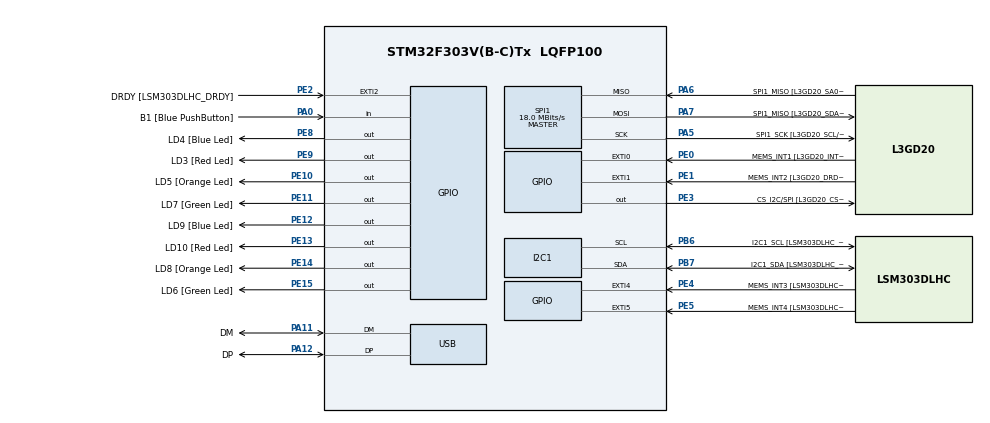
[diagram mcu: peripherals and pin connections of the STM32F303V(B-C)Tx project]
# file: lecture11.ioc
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FREERTOS.Tasks01=defaultTask,0,128,StartDefaultTask,Default,NULL,Dynamic,NULL,NULL;myTask02,-3,128,StartTask02,Default,NULL,Dynamic,NULL,NULL;myTask03,-3,128,StartTask03,Default,NULL,Dynamic,NULL,NULL
I2C1.Timing-I2C=0x2000090E
Mcu.Family=STM32F3
Mcu.Name=STM32F303V(B-C)Tx
Mcu.Package=LQFP100
NVIC.PriorityGroup=NVIC_PRIORITYGROUP_4
NVIC.TIM1_UP_TIM16_IRQn=true\:0\:0\:false\:false\:true\:false\:false
NVIC.TimeBase=TIM1_UP_TIM16_IRQn
NVIC.TimeBaseIP=TIM1
PA0.GPIO_Label=B1 [Blue PushButton]
PA0.Signal=GPIO_Input
PA11.GPIO_Label=DM
PA11.Mode=Device
PA11.Signal=USB_DM
PA12.GPIO_Label=DP
PA12.Mode=Device
PA12.Signal=USB_DP
PA13.GPIO_Label=SWDIO
PA13.Mode=Serial_Wire
PA13.Signal=SYS_JTMS-SWDIO
PA14.GPIO_Label=SWCLK
PA14.Mode=Serial_Wire
PA14.Signal=SYS_JTCK-SWCLK
PA5.GPIO_Label=SPI1_SCK [L3GD20_SCL/SPC]
PA5.Mode=Full_Duplex_Master
PA5.Signal=SPI1_SCK
PA6.GPIO_Label=SPI1_MISO [L3GD20_SA0/SDO]
PA6.Mode=Full_Duplex_Master
PA6.Signal=SPI1_MISO
PA7.GPIO_Label=SPI1_MISO [L3GD20_SDA/SDI/SDO]
PA7.Mode=Full_Duplex_Master
PA7.Signal=SPI1_MOSI
PB3.GPIO_Label=SWO
PB3.Signal=SYS_JTDO-TRACESWO
PB6.GPIO_Label=I2C1_SCL [LSM303DLHC_SCL]
PB6.Mode=I2C
PB6.Signal=I2C1_SCL
PB7.GPIO_Label=I2C1_SDA [LSM303DLHC_SDA]
PB7.Mode=I2C
PB7.Signal=I2C1_SDA
PC14-OSC32_IN.GPIO_Label=OSC32_IN
PC14-OSC32_IN.Signal=RCC_OSC32_IN
PC15-OSC32_OUT.GPIO_Label=OSC32_OUT
PC15-OSC32_OUT.Signal=RCC_OSC32_OUT
PE0.GPIO_Label=MEMS_INT1 [L3GD20_INT1]
PE0.GPIO_ModeDefaultEXTI=GPIO_MODE_EVT_RISING
PE0.Signal=GPXTI0
PE1.GPIO_Label=MEMS_INT2 [L3GD20_DRDY/INT2]
PE1.GPIO_ModeDefaultEXTI=GPIO_MODE_EVT_RISING
PE1.Signal=GPXTI1
PE10.GPIO_Label=LD5 [Orange Led]
PE10.Signal=GPIO_Output
PE11.GPIO_Label=LD7 [Green Led]
PE11.Signal=GPIO_Output
PE12.GPIO_Label=LD9 [Blue Led]
PE12.Signal=GPIO_Output
PE13.GPIO_Label=LD10 [Red Led]
PE13.Signal=GPIO_Output
PE14.GPIO_Label=LD8 [Orange Led]
PE14.Signal=GPIO_Output
PE15.GPIO_Label=LD6 [Green Led]
PE15.Signal=GPIO_Output
PE2.GPIO_Label=DRDY [LSM303DLHC_DRDY]
PE2.GPIO_ModeDefaultEXTI=GPIO_MODE_EVT_RISING
PE2.Signal=GPXTI2
PE3.GPIO_Label=CS_I2C/SPI [L3GD20_CS_I2C/SPI]
PE3.Signal=GPIO_Output
PE4.GPIO_Label=MEMS_INT3 [LSM303DLHC_INT1]
PE4.GPIO_ModeDefaultEXTI=GPIO_MODE_EVT_RISING
PE4.Signal=GPXTI4
PE5.GPIO_Label=MEMS_INT4 [LSM303DLHC_INT2]
PE5.GPIO_ModeDefaultEXTI=GPIO_MODE_EVT_RISING
PE5.Signal=GPXTI5
PE8.GPIO_Label=LD4 [Blue Led]
PE8.Signal=GPIO_Output
PE9.GPIO_Label=LD3 [Red Led]
PE9.Signal=GPIO_Output
PF0-OSC_IN.GPIO_Label=OSC_IN
PF0-OSC_IN.Mode=HSE-External-Clock-Source
PF0-OSC_IN.Signal=RCC_OSC_IN
PF1-OSC_OUT.GPIO_Label=OSC_OUT
PF1-OSC_OUT.Signal=RCC_OSC_OUT
ProjectManager.HeapSize=0x2000
ProjectManager.StackSize=0x4000
ProjectManager.TargetToolchain=MDK-ARM V5
RCC.AHBFreq_Value=72000000
RCC.APB1CLKDivider=RCC_HCLK_DIV2
RCC.APB1Freq_Value=36000000
RCC.APB1TimFreq_Value=72000000
RCC.APB2Freq_Value=72000000
RCC.APB2TimFreq_Value=72000000
RCC.CortexFreq_Value=72000000
RCC.HCLKFreq_Value=72000000
RCC.HSE_VALUE=8000000
RCC.HSI_VALUE=8000000
RCC.LSE_VALUE=32768
RCC.PLLMUL=RCC_PLL_MUL9
RCC.PRESCALERUSB=RCC_USBCLKSOURCE_PLL_DIV1_5
RCC.SYSCLKFreq_VALUE=72000000
RCC.SYSCLKSourceVirtual=RCC_SYSCLKSOURCE_PLLCLK
RCC.USBFreq_Value=48000000
SPI1.BaudRatePrescaler=SPI_BAUDRATEPRESCALER_4
SPI1.BaudRatePrescaler-Full_Duplex_Master=SPI_BAUDRATEPRESCALER_2
SPI1.CalculateBaudRate=18.0 MBits/s
SPI1.CalculateBaudRate-Full_Duplex_Master=24.0 MBits/s
SPI1.Direction=SPI_DIRECTION_2LINES
SPI1.Mode=SPI_MODE_MASTER
SPI1.Mode-Full_Duplex_Master=SPI_MODE_MASTER
SPI1.VirtualType=VM_MASTER
VP_FREERTOS_VS_ENABLE.Mode=Enabled
VP_SYS_VS_tim1.Mode=TIM1
board=STM32F3DISCOVERY

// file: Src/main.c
/* USER CODE BEGIN Header */
/**
  ******************************************************************************
  * @file           : main.c
  * @brief          : Create program "The Dining Philosophers"
  ******************************************************************************
  * @attention
  *
  * <h2><center>&copy; Copyright (c) 2020 STMicroelectronics.
  * All rights reserved.</center></h2>
  *
  * This software component is licensed by ST under Ultimate Liberty license
  * SLA0044, the "License"; You may not use this file except in compliance with
  * the License. You may obtain a copy of the License at:
  *                             www.st.com/SLA0044
  *
  ******************************************************************************
  */
/* USER CODE END Header */

#include "main.h"
#include "stm32f3xx_hal.h"
#include "cmsis_os.h"
#include "Init.h"
#include "FreeRTOS.h"
#include "task.h"
#include "queue.h"

/* USER CODE BEGIN Includes */
#define  ARISTOTLE 0
#define  PLATON 1
#define  NIETZSCHE 2
#define  KANT 3
#define  SOCRAT 4
/* USER CODE END Includes */

TaskHandle_t myTaskHandle[5];
/*for each of philosofer*/
SemaphoreHandle_t xSemaphorePhilosofer[5] = {NULL};
/* fork taking */
SemaphoreHandle_t xSemaphoreTakingFork = NULL;

volatile uint32_t TIM1_Count = 0;
volatile uint32_t TIM1_Count_Sec = 0;
volatile uint8_t philosopherStatus[5] = {0};

void Philosopher_1(void* pvParameters);
void Philosopher_2(void* pvParameters);
void Philosopher_3(void* pvParameters);
void Philosopher_4(void* pvParameters);
void Philosopher_5(void* pvParameters);

void t_Fork (uint8_t);
void t_Eat(uint8_t);
void p_Fork (uint8_t);
/* ---------------------------------------------------------------------------*/
int main(void)
{

/* Reset of all peripherals, Initializes the Flash interface and the Systick. */
  HAL_Init();

/* Configure the system clock */
  SystemClock_Config();

  /* Initialize all configured peripherals */
  MX_GPIO_Init();
  MX_I2C1_Init();
  MX_SPI1_Init();
  MX_USB_PCD_Init();
	/* creating semaphors for each forks */
	for(int i = 0; i < 5; i++)
	{
		xSemaphorePhilosofer[i] = xSemaphoreCreateBinary();
		if( xSemaphorePhilosofer[i]  == NULL )
		{    /* There was insufficient FreeRTOS heap available for the semaphore to be created successfully. */
				 for (;;);
		}
		else
		{
				if( xSemaphoreGive( xSemaphorePhilosofer[i]  ) != pdTRUE )
				{
					for (;;);
				}
		}
	}
	/* semaphor for taking fork */
	xSemaphoreTakingFork = xSemaphoreCreateBinary();
	if( xSemaphoreTakingFork  == NULL )
		{    /* There was insufficient FreeRTOS heap available for the semaphore to be created successfully. */
				 for (;;);
		}
		else
		{
				if( xSemaphoreGive(xSemaphoreTakingFork) != pdTRUE )
				{
					for (;;);
				}
		}

		xTaskCreate(Philosopher_1,       /* Function that implements the task. */
								"philosopher1",          /* Text name for the task. */
								64,      /* Stack size in words, not bytes. */
								NULL,    /* Parameter passed into the task. */
								0,/* Priority at which the task is created. */
								&myTaskHandle[0] );

		xTaskCreate(Philosopher_2,       /* Function that implements the task. */
								"philosopher2",          /* Text name for the task. */
								64,      /* Stack size in words, not bytes. */
								NULL,    /* Parameter passed into the task. */
								0,/* Priority at which the task is created. */
								&myTaskHandle[1] );

		xTaskCreate(Philosopher_3,       /* Function that implements the task. */
								"philosopher3",          /* Text name for the task. */
								64,      /* Stack size in words, not bytes. */
								NULL,    /* Parameter passed into the task. */
								0,/* Priority at which the task is created. */
								&myTaskHandle[2] );
		xTaskCreate(Philosopher_4,       /* Function that implements the task. */
								"philosopher4",          /* Text name for the task. */
								64,      /* Stack size in words, not bytes. */
								NULL,    /* Parameter passed into the task. */
								0,/* Priority at which the task is created. */
								&myTaskHandle[3] );
		xTaskCreate(Philosopher_5,       /* Function that implements the task. */
								"philosopher5",          /* Text name for the task. */
								64,      /* Stack size in words, not bytes. */
								NULL,    /* Parameter passed into the task. */
								0,/* Priority at which the task is created. */
								&myTaskHandle[4] );
	/* Start scheduler */
  osKernelStart();

  while (1)
  {
  }
}
/**
  * @brief  executed when one of the philosophers try to take a fork.
  * @param  Number of philosopher who want to take a fork.
  */
void t_Fork (uint8_t philosopher)
{
	if (xSemaphoreTakingFork != NULL)
  {
    if(osSemaphoreWait(xSemaphoreTakingFork , 100) == osOK)
    {
			philosopherStatus[philosopher] = 1;
			/* taking forks */
			t_Eat(philosopher);
			/* taking semaphor for philosofer how waithing for forks */
			osSemaphoreRelease(xSemaphoreTakingFork);
		}
		else
		{
			/* taking semaphor for philosopher how whants to eat */
			xSemaphoreTake( xSemaphorePhilosofer[philosopher],  portMAX_DELAY );
		}
	}
}
/**
  * @brief  executed when one of the philosophers test forks.
  * @param  Number of philosopher who want release the forks.
  */
void t_Eat(uint8_t philosopher)
{
		if (philosopherStatus[philosopher] == 1
				  && philosopherStatus[(philosopher + 5 - 1) % 5] != 2
					&& philosopherStatus[(philosopher + 1) % 5] != 2)
			{
				philosopherStatus[philosopher] = 2;
				xSemaphoreGive( xSemaphorePhilosofer[philosopher] );
			}
}
/**
  * @brief  executed when one of the philosophers releasin the forks.
  * @param  Number of philosopher who want release the forks.
  */
void p_Fork (uint8_t philosopher)
{
	if(osSemaphoreWait(xSemaphoreTakingFork , 100) == osOK)
	{
		philosopherStatus[philosopher] = 0;
		t_Eat((philosopher + 5 - 1) % 5);
		t_Eat((philosopher + 1) % 5);
		osSemaphoreRelease(xSemaphoreTakingFork);
	}
}

void Philosopher_1( void* pvParameters)
{
	for(;;)
  {
		/*  thinking */
		osDelay(100);
		/*  take forks */
		t_Fork (ARISTOTLE);

		if(xSemaphoreTake( xSemaphorePhilosofer[ARISTOTLE],  portMAX_DELAY ) == pdTRUE && philosopherStatus[ARISTOTLE] == 2)
		{
				/* eating */
				HAL_GPIO_WritePin(LEDPORT, LED02, GPIO_PIN_RESET);
				HAL_GPIO_WritePin(LEDPORT, LED01, GPIO_PIN_SET);
				osDelay(100);
				HAL_GPIO_WritePin(LEDPORT, LED01, GPIO_PIN_RESET);
				HAL_GPIO_WritePin(LEDPORT, LED02, GPIO_PIN_SET);
				osDelay(100);
				/* eating */
				xSemaphoreGive( xSemaphorePhilosofer[ARISTOTLE]);
				p_Fork(ARISTOTLE);
		}
		else
		{
			osDelay(10);
		}
	}
}

void Philosopher_2( void* pvParameters)
{
	for(;;)
  {
		/*  thinking */
		osDelay(100);
		/*  take forks */
		t_Fork (PLATON);

		if(xSemaphoreTake( xSemaphorePhilosofer[PLATON],  portMAX_DELAY ) == pdTRUE && philosopherStatus[PLATON] == 2)
		{
				/* eating */
				HAL_GPIO_WritePin(LEDPORT, LED04, GPIO_PIN_RESET);
				HAL_GPIO_WritePin(LEDPORT, LED03, GPIO_PIN_SET);
				osDelay(100);
				HAL_GPIO_WritePin(LEDPORT, LED03, GPIO_PIN_RESET);
				HAL_GPIO_WritePin(LEDPORT, LED04, GPIO_PIN_SET);
				osDelay(100);
				/* eating */
				xSemaphoreGive(xSemaphorePhilosofer[PLATON]);
				p_Fork(PLATON);
			}
		else
		{
			osDelay(10);
		}

	}
}

void Philosopher_3( void* pvParameters)
{
	for(;;)
  {
		/*  thinking */
		osDelay(70);
		/*  take forks */
		t_Fork (NIETZSCHE);

		if(xSemaphoreTake( xSemaphorePhilosofer[NIETZSCHE],  portMAX_DELAY ) == pdTRUE && philosopherStatus[NIETZSCHE] == 2)
		{
				/* eating */
				HAL_GPIO_WritePin(LEDPORT, LED06, GPIO_PIN_RESET);
				HAL_GPIO_WritePin(LEDPORT, LED05, GPIO_PIN_SET);
				osDelay(100);
				HAL_GPIO_WritePin(LEDPORT, LED05, GPIO_PIN_RESET);
				HAL_GPIO_WritePin(LEDPORT, LED06, GPIO_PIN_SET);
				osDelay(100);
				/* eating */
				xSemaphoreGive(xSemaphorePhilosofer[NIETZSCHE]);
				p_Fork(NIETZSCHE);
			}
		else
		{
			osDelay(10);
		}

	}
}

void Philosopher_4( void* pvParameters)
{
	for(;;)
  {
		/*  thinking */
		osDelay(100);
		/*  take forks */
		t_Fork (KANT);

		if(xSemaphoreTake( xSemaphorePhilosofer[KANT],  portMAX_DELAY ) == pdTRUE && philosopherStatus[KANT] == 2)
		{
				/* eating */
				HAL_GPIO_WritePin(LEDPORT, LED08, GPIO_PIN_RESET);
				HAL_GPIO_WritePin(LEDPORT, LED07, GPIO_PIN_SET);
				osDelay(100);
				HAL_GPIO_WritePin(LEDPORT, LED07, GPIO_PIN_RESET);
				HAL_GPIO_WritePin(LEDPORT, LED08, GPIO_PIN_SET);
				osDelay(100);
				/* eating */
				xSemaphoreGive(xSemaphorePhilosofer[KANT]);
				p_Fork(KANT);
			}
		else
		{
			osDelay(10);
		}
	}
}

void Philosopher_5( void* pvParameters)
{
	for(;;)
  {
		/*  thinking */
		osDelay(100);
		/*  take forks */
		t_Fork (SOCRAT);

		if(xSemaphoreTake( xSemaphorePhilosofer[SOCRAT],  portMAX_DELAY ) == pdTRUE && philosopherStatus[SOCRAT] == 2)
		{
		  	osDelay(100);

				xSemaphoreGive(xSemaphorePhilosofer[SOCRAT]);
				p_Fork(SOCRAT);
			}
		else
		{
			osDelay(10);
		}
	}
}

void HAL_TIM_PeriodElapsedCallback(TIM_HandleTypeDef *htim)
{
  if (htim->Instance == TIM1) {
    HAL_IncTick();
  }
	TIM1_Count++;
  if(TIM1_Count%1000==0)
  {
    TIM1_Count_Sec++;
  }
  if(TIM1_Count>=10000000)
	{
		TIM1_Count=0;
	}
}

void _Error_Handler(char *file, int line)
{
  while(1)
  {
  }
}
